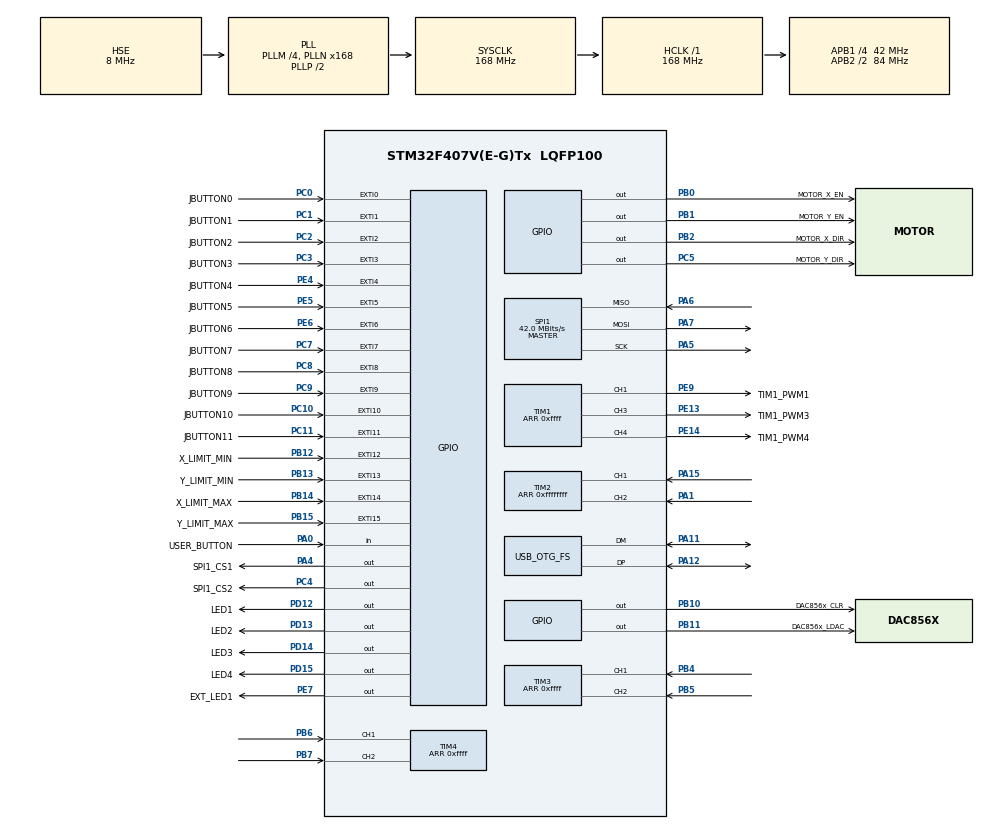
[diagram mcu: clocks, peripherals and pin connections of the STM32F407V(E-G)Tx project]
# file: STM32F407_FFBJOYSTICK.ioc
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Dma.Request0=SPI1_RX
Dma.Request1=SPI1_TX
Dma.SPI1_RX.0.Direction=DMA_PERIPH_TO_MEMORY
Dma.SPI1_RX.0.FIFOMode=DMA_FIFOMODE_DISABLE
Dma.SPI1_RX.0.Instance=DMA2_Stream2
Dma.SPI1_RX.0.MemDataAlignment=DMA_MDATAALIGN_BYTE
Dma.SPI1_RX.0.MemInc=DMA_MINC_ENABLE
Dma.SPI1_RX.0.Mode=DMA_NORMAL
Dma.SPI1_RX.0.PeriphDataAlignment=DMA_PDATAALIGN_BYTE
Dma.SPI1_RX.0.PeriphInc=DMA_PINC_DISABLE
Dma.SPI1_RX.0.Priority=DMA_PRIORITY_LOW
Dma.SPI1_TX.1.Direction=DMA_MEMORY_TO_PERIPH
Dma.SPI1_TX.1.FIFOMode=DMA_FIFOMODE_DISABLE
Dma.SPI1_TX.1.Instance=DMA2_Stream3
Dma.SPI1_TX.1.MemDataAlignment=DMA_MDATAALIGN_BYTE
Dma.SPI1_TX.1.MemInc=DMA_MINC_ENABLE
Dma.SPI1_TX.1.Mode=DMA_NORMAL
Dma.SPI1_TX.1.PeriphDataAlignment=DMA_PDATAALIGN_BYTE
Dma.SPI1_TX.1.PeriphInc=DMA_PINC_DISABLE
Dma.SPI1_TX.1.Priority=DMA_PRIORITY_LOW
Mcu.Family=STM32F4
Mcu.Name=STM32F407V(E-G)Tx
Mcu.Package=LQFP100
NVIC.DMA2_Stream2_IRQn=true\:0\:0\:false\:false\:true\:false\:true
NVIC.DMA2_Stream3_IRQn=true\:0\:0\:false\:false\:true\:false\:true
NVIC.EXTI0_IRQn=true\:0\:0\:false\:false\:true\:true\:true
NVIC.EXTI15_10_IRQn=true\:0\:0\:false\:false\:true\:true\:true
NVIC.EXTI1_IRQn=true\:0\:0\:false\:false\:true\:true\:true
NVIC.EXTI2_IRQn=true\:0\:0\:false\:false\:true\:true\:true
NVIC.EXTI3_IRQn=true\:0\:0\:false\:false\:true\:true\:true
NVIC.EXTI4_IRQn=true\:0\:0\:false\:false\:true\:true\:true
NVIC.EXTI9_5_IRQn=true\:0\:0\:false\:false\:true\:true\:true
NVIC.OTG_FS_IRQn=true\:0\:0\:false\:false\:true\:true\:true
NVIC.PriorityGroup=NVIC_PRIORITYGROUP_4
NVIC.SPI1_IRQn=true\:0\:0\:false\:false\:true\:true\:true
NVIC.TIM2_IRQn=true\:0\:0\:false\:false\:true\:true\:true
NVIC.TIM3_IRQn=true\:0\:0\:false\:false\:true\:true\:true
NVIC.TIM4_IRQn=true\:0\:0\:false\:false\:true\:true\:true
PA0-WKUP.GPIO_Label=USER_BUTTON
PA0-WKUP.Signal=GPIO_Input
PA1.GPIO_PuPd=GPIO_PULLUP
PA1.GPIO_Speed=GPIO_SPEED_FREQ_HIGH
PA1.Signal=S_TIM2_CH2
PA11.Mode=Device_Only
PA11.Signal=USB_OTG_FS_DM
PA12.Mode=Device_Only
PA12.Signal=USB_OTG_FS_DP
PA13.Mode=Serial_Wire
PA13.Signal=SYS_JTMS-SWDIO
PA14.Mode=Serial_Wire
PA14.Signal=SYS_JTCK-SWCLK
PA15.GPIO_PuPd=GPIO_PULLUP
PA15.GPIO_Speed=GPIO_SPEED_FREQ_HIGH
PA15.Signal=S_TIM2_CH1_ETR
PA4.GPIO_Label=SPI1_CS1
PA4.Signal=GPIO_Output
PA5.Mode=Full_Duplex_Master
PA5.Signal=SPI1_SCK
PA6.Mode=Full_Duplex_Master
PA6.Signal=SPI1_MISO
PA7.Mode=Full_Duplex_Master
PA7.Signal=SPI1_MOSI
PB0.GPIO_Label=MOTOR_X_EN
PB0.GPIO_Speed=GPIO_SPEED_FREQ_HIGH
PB0.Signal=GPIO_Output
PB1.GPIO_Label=MOTOR_Y_EN
PB1.GPIO_Speed=GPIO_SPEED_FREQ_HIGH
PB1.Signal=GPIO_Output
PB10.GPIO_Label=DAC856x_CLR
PB10.Signal=GPIO_Output
PB11.GPIO_Label=DAC856x_LDAC
PB11.Signal=GPIO_Output
PB12.GPIO_Label=X_LIMIT_MIN
PB12.GPIO_ModeDefaultEXTI=GPIO_MODE_IT_RISING_FALLING
PB12.GPIO_PuPd=GPIO_PULLUP
PB12.Signal=GPXTI12
PB13.GPIO_Label=Y_LIMIT_MIN
PB13.GPIO_ModeDefaultEXTI=GPIO_MODE_IT_RISING_FALLING
PB13.GPIO_PuPd=GPIO_PULLUP
PB13.Signal=GPXTI13
PB14.GPIO_Label=X_LIMIT_MAX
PB14.GPIO_ModeDefaultEXTI=GPIO_MODE_IT_RISING_FALLING
PB14.GPIO_PuPd=GPIO_PULLUP
PB14.Signal=GPXTI14
PB15.GPIO_Label=Y_LIMIT_MAX
PB15.GPIO_ModeDefaultEXTI=GPIO_MODE_IT_RISING_FALLING
PB15.GPIO_PuPd=GPIO_PULLUP
PB15.Signal=GPXTI15
PB2.GPIO_Label=MOTOR_X_DIR
PB2.Signal=GPIO_Output
PB4.Signal=S_TIM3_CH1
PB5.Signal=S_TIM3_CH2
PB6.Signal=S_TIM4_CH1
PB7.Signal=S_TIM4_CH2
PC0.GPIO_Label=JBUTTON0
PC0.GPIO_ModeDefaultEXTI=GPIO_MODE_IT_RISING_FALLING
PC0.GPIO_PuPd=GPIO_PULLUP
PC0.Signal=GPXTI0
PC1.GPIO_Label=JBUTTON1
PC1.GPIO_ModeDefaultEXTI=GPIO_MODE_IT_RISING_FALLING
PC1.GPIO_PuPd=GPIO_PULLUP
PC1.Signal=GPXTI1
PC10.GPIO_Label=JBUTTON10
PC10.GPIO_ModeDefaultEXTI=GPIO_MODE_IT_RISING_FALLING
PC10.GPIO_PuPd=GPIO_PULLUP
PC10.Signal=GPXTI10
PC11.GPIO_Label=JBUTTON11
PC11.GPIO_ModeDefaultEXTI=GPIO_MODE_IT_RISING_FALLING
PC11.GPIO_PuPd=GPIO_PULLUP
PC11.Signal=GPXTI11
PC2.GPIO_Label=JBUTTON2
PC2.GPIO_ModeDefaultEXTI=GPIO_MODE_IT_RISING_FALLING
PC2.GPIO_PuPd=GPIO_PULLUP
PC2.Signal=GPXTI2
PC3.GPIO_Label=JBUTTON3
PC3.GPIO_ModeDefaultEXTI=GPIO_MODE_IT_RISING_FALLING
PC3.GPIO_PuPd=GPIO_PULLUP
PC3.Signal=GPXTI3
PC4.GPIO_Label=SPI1_CS2
PC4.GPIO_Speed=GPIO_SPEED_FREQ_HIGH
PC4.PinState=GPIO_PIN_SET
PC4.Signal=GPIO_Output
PC5.GPIO_Label=MOTOR_Y_DIR
PC5.Signal=GPIO_Output
PC7.GPIO_Label=JBUTTON7
PC7.GPIO_ModeDefaultEXTI=GPIO_MODE_IT_RISING_FALLING
PC7.GPIO_PuPd=GPIO_PULLUP
PC7.Signal=GPXTI7
PC8.GPIO_Label=JBUTTON8
PC8.GPIO_ModeDefaultEXTI=GPIO_MODE_IT_RISING_FALLING
PC8.GPIO_PuPd=GPIO_PULLUP
PC8.Signal=GPXTI8
PC9.GPIO_Label=JBUTTON9
PC9.GPIO_ModeDefaultEXTI=GPIO_MODE_IT_RISING_FALLING
PC9.GPIO_PuPd=GPIO_PULLUP
PC9.Signal=GPXTI9
PD12.GPIO_Label=LED1
PD12.GPIO_Speed=GPIO_SPEED_FREQ_HIGH
PD12.Signal=GPIO_Output
PD13.GPIO_Label=LED2
PD13.GPIO_Speed=GPIO_SPEED_FREQ_HIGH
PD13.Signal=GPIO_Output
PD14.GPIO_Label=LED3
PD14.GPIO_Speed=GPIO_SPEED_FREQ_HIGH
PD14.Signal=GPIO_Output
PD15.GPIO_Label=LED4
PD15.GPIO_Speed=GPIO_SPEED_FREQ_HIGH
PD15.Signal=GPIO_Output
PE13.GPIO_Label=TIM1_PWM3
PE13.GPIO_Speed=GPIO_SPEED_FREQ_HIGH
PE13.Signal=S_TIM1_CH3
PE14.GPIO_Label=TIM1_PWM4
PE14.GPIO_Speed=GPIO_SPEED_FREQ_HIGH
PE14.Signal=S_TIM1_CH4
PE4.GPIO_Label=JBUTTON4
PE4.GPIO_ModeDefaultEXTI=GPIO_MODE_IT_RISING_FALLING
PE4.GPIO_PuPd=GPIO_PULLUP
PE4.Signal=GPXTI4
PE5.GPIO_Label=JBUTTON5
PE5.GPIO_ModeDefaultEXTI=GPIO_MODE_IT_RISING_FALLING
PE5.GPIO_PuPd=GPIO_PULLUP
PE5.Signal=GPXTI5
PE6.GPIO_Label=JBUTTON6
PE6.GPIO_ModeDefaultEXTI=GPIO_MODE_IT_RISING_FALLING
PE6.GPIO_PuPd=GPIO_PULLUP
PE6.Signal=GPXTI6
PE7.GPIO_Label=EXT_LED1
PE7.GPIO_Speed=GPIO_SPEED_FREQ_HIGH
PE7.PinState=GPIO_PIN_RESET
PE7.Signal=GPIO_Output
PE9.GPIO_Label=TIM1_PWM1
PE9.GPIO_Speed=GPIO_SPEED_FREQ_HIGH
PE9.Signal=S_TIM1_CH1
PH0-OSC_IN.Mode=HSE-External-Oscillator
PH0-OSC_IN.Signal=RCC_OSC_IN
PH1-OSC_OUT.Mode=HSE-External-Oscillator
PH1-OSC_OUT.Signal=RCC_OSC_OUT
ProjectManager.HeapSize=0x400
ProjectManager.StackSize=0x2000
ProjectManager.TargetToolchain=STM32CubeIDE
RCC.48MHZClocksFreq_Value=48000000
RCC.AHBFreq_Value=168000000
RCC.APB1CLKDivider=RCC_HCLK_DIV4
RCC.APB1Freq_Value=42000000
RCC.APB1TimFreq_Value=84000000
RCC.APB2CLKDivider=RCC_HCLK_DIV2
RCC.APB2Freq_Value=84000000
RCC.APB2TimFreq_Value=168000000
RCC.CortexFreq_Value=168000000
RCC.HCLKFreq_Value=168000000
RCC.HSE_VALUE=8000000
RCC.HSI_VALUE=16000000
RCC.LSE_VALUE=32768
RCC.PLLM=4
RCC.PLLN=168
RCC.PLLQ=7
RCC.SYSCLKFreq_VALUE=168000000
RCC.SYSCLKSource=RCC_SYSCLKSOURCE_PLLCLK
RCC.VCOOutputFreq_Value=336000000
SH.S_TIM1_CH1.0=TIM1_CH1,PWM Generation1 CH1
SH.S_TIM1_CH3.0=TIM1_CH3,PWM Generation3 CH3
SH.S_TIM1_CH4.0=TIM1_CH4,PWM Generation4 CH4
SH.S_TIM2_CH1_ETR.0=TIM2_CH1,Encoder_Interface
SH.S_TIM2_CH2.0=TIM2_CH2,Encoder_Interface
SH.S_TIM3_CH1.0=TIM3_CH1,Encoder_Interface
SH.S_TIM3_CH2.0=TIM3_CH2,Encoder_Interface
SH.S_TIM4_CH1.0=TIM4_CH1,Encoder_Interface
SH.S_TIM4_CH2.0=TIM4_CH2,Encoder_Interface
SPI1.CalculateBaudRate=42.0 MBits/s
SPI1.Direction=SPI_DIRECTION_2LINES
SPI1.Mode=SPI_MODE_MASTER
SPI1.VirtualType=VM_MASTER
TIM1.AutoReloadPreload=TIM_AUTORELOAD_PRELOAD_ENABLE
TIM1.Channel-PWM\ Generation1\ CH1=TIM_CHANNEL_1
TIM1.Channel-PWM\ Generation3\ CH3=TIM_CHANNEL_3
TIM1.Channel-PWM\ Generation4\ CH4=TIM_CHANNEL_4
TIM1.Period=0xffff
TIM10.Prescaler=167
TIM2.AutoReloadPreload=TIM_AUTORELOAD_PRELOAD_DISABLE
TIM2.CounterMode=TIM_COUNTERMODE_CENTERALIGNED1
TIM2.EncoderMode=TIM_ENCODERMODE_TI12
TIM2.IC1Filter=10
TIM2.IC1Polarity=TIM_ICPOLARITY_FALLING
TIM2.IC2Filter=10
TIM2.IC2Polarity=TIM_ICPOLARITY_FALLING
TIM2.Period=0xffffffff
TIM3.AutoReloadPreload=TIM_AUTORELOAD_PRELOAD_ENABLE
TIM3.CounterMode=TIM_COUNTERMODE_CENTERALIGNED1
TIM3.EncoderMode=TIM_ENCODERMODE_TI12
TIM3.IC1Polarity=TIM_ICPOLARITY_FALLING
TIM3.IC2Polarity=TIM_ICPOLARITY_FALLING
TIM3.Period=0xffff
TIM4.AutoReloadPreload=TIM_AUTORELOAD_PRELOAD_ENABLE
TIM4.CounterMode=TIM_COUNTERMODE_CENTERALIGNED1
TIM4.EncoderMode=TIM_ENCODERMODE_TI12
TIM4.IC1Filter=0
TIM4.IC1Polarity=TIM_ICPOLARITY_FALLING
TIM4.IC2Filter=0
TIM4.IC2Polarity=TIM_ICPOLARITY_FALLING
TIM4.Period=0xffff
USB_OTG_FS.VirtualMode=Device_Only
VP_TIM10_VS_ClockSourceINT.Mode=Enable_Timer
VP_TIM1_VS_ClockSourceINT.Mode=Internal
board=custom

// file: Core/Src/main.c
/* USER CODE BEGIN Header */
/**
 ******************************************************************************
 * @file           : main.c
 * @brief          : Main program body
 ******************************************************************************
 * @attention
 *
 * <h2><center>&copy; Copyright (c) 2021 STMicroelectronics.
 * All rights reserved.</center></h2>
 *
 * This software component is licensed by ST under Ultimate Liberty license
 * SLA0044, the "License"; You may not use this file except in compliance with
 * the License. You may obtain a copy of the License at:
 *                             www.st.com/SLA0044
 *
 ******************************************************************************
 */
/* USER CODE END Header */
#include "main.h"
#include "dma.h"
#include "spi.h"
#include "tim.h"
#include "gpio.h"

/* USER CODE BEGIN Includes */
#include "cppmain.h"
extern void cppmain ();
/* USER CODE END Includes */

/* USER CODE BEGIN PTD */

int __io_putchar(int ch) {
ITM_SendChar(ch);
return ch;
}
/* USER CODE END PTD */

void SystemClock_Config(void);

int main(void)
{

  /* MCU Configuration--------------------------------------------------------*/

  /* Reset of all peripherals, Initializes the Flash interface and the Systick. */
  HAL_Init();

  /* Configure the system clock */
  SystemClock_Config();

  /* Initialize all configured peripherals */
  MX_GPIO_Init();
  MX_DMA_Init();
  MX_TIM3_Init();
  MX_TIM4_Init();
  MX_TIM10_Init();
  MX_TIM1_Init();
  MX_SPI1_Init();
  MX_TIM2_Init();
  /* USER CODE BEGIN 2 */

  /* ***************************************** WARNING !!! ******************************************************
   * After using STM32CubeMX or STM32CubeIDE generation code. you just delete 2 files: usb_otg.c and usb_otg.h	*
   * this files will conflig with in this project USB device Joystick module.   								*
   * 																											*
   * ************************************************************************************************************/
  MX_USB_DEVICE_Init ();
  htim10.Instance->CR1 = 1; // Enable microsecond clock
  delay_us (1000);
  /* USER CODE END 2 */

  /* Infinite loop */
  while (1)
    {

    /* USER CODE BEGIN 3 */
      cppmain ();
    }
  /* USER CODE END 3 */
}

void SystemClock_Config(void)
{
  RCC_OscInitTypeDef RCC_OscInitStruct = {0};
  RCC_ClkInitTypeDef RCC_ClkInitStruct = {0};

  /** Configure the main internal regulator output voltage
  */
  __HAL_RCC_PWR_CLK_ENABLE();
  __HAL_PWR_VOLTAGESCALING_CONFIG(PWR_REGULATOR_VOLTAGE_SCALE1);
  /** Initializes the RCC Oscillators according to the specified parameters
  * in the RCC_OscInitTypeDef structure.
  */
  RCC_OscInitStruct.OscillatorType = RCC_OSCILLATORTYPE_HSE;
  RCC_OscInitStruct.HSEState = RCC_HSE_ON;
  RCC_OscInitStruct.PLL.PLLState = RCC_PLL_ON;
  RCC_OscInitStruct.PLL.PLLSource = RCC_PLLSOURCE_HSE;
  RCC_OscInitStruct.PLL.PLLM = 4;
  RCC_OscInitStruct.PLL.PLLN = 168;
  RCC_OscInitStruct.PLL.PLLP = RCC_PLLP_DIV2;
  RCC_OscInitStruct.PLL.PLLQ = 7;
  if (HAL_RCC_OscConfig(&RCC_OscInitStruct) != HAL_OK)
  {
    Error_Handler();
  }
  /** Initializes the CPU, AHB and APB buses clocks
  */
  RCC_ClkInitStruct.ClockType = RCC_CLOCKTYPE_HCLK|RCC_CLOCKTYPE_SYSCLK
                              |RCC_CLOCKTYPE_PCLK1|RCC_CLOCKTYPE_PCLK2;
  RCC_ClkInitStruct.SYSCLKSource = RCC_SYSCLKSOURCE_PLLCLK;
  RCC_ClkInitStruct.AHBCLKDivider = RCC_SYSCLK_DIV1;
  RCC_ClkInitStruct.APB1CLKDivider = RCC_HCLK_DIV4;
  RCC_ClkInitStruct.APB2CLKDivider = RCC_HCLK_DIV2;

  if (HAL_RCC_ClockConfig(&RCC_ClkInitStruct, FLASH_LATENCY_5) != HAL_OK)
  {
    Error_Handler();
  }
}

void Error_Handler(void)
{
  /* USER CODE BEGIN Error_Handler_Debug */
  /* User can add his own implementation to report the HAL error return state */
  __disable_irq ();
  while (1)
    {
    }
  /* USER CODE END Error_Handler_Debug */
}

/************************ (C) COPYRIGHT STMicroelectronics *****END OF FILE****/
